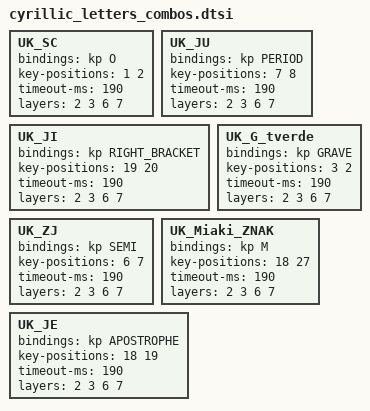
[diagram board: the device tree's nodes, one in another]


//---------------------------------------------    For OS in QWERTY    ---------------------------------------------
UK_SC {
    bindings = <&kp O>;
    key-positions = <1 2>;
    timeout-ms = <190>;
    layers = <2 3 6 7>;
};

UK_JU {
    bindings = <&kp PERIOD>;
    key-positions = <7 8>;
    timeout-ms = <190>;
    layers = <2 3 6 7>;
};

UK_JI {
    bindings = <&kp RIGHT_BRACKET>;
    key-positions = <19 20>;
    timeout-ms = <190>;
    layers = <2 3 6 7>;
};

UK_G_tverde {
    bindings = <&kp GRAVE>;
    key-positions = <3 2>;
    timeout-ms = <190>;
    layers = <2 3 6 7>;
};

UK_ZJ {
    bindings = <&kp SEMI>;
    key-positions = <6 7>;
    timeout-ms = <190>;
    layers = <2 3 6 7>;
};

UK_Miaki_ZNAK {
    bindings = <&kp M>;
    key-positions = <18 27>;
    timeout-ms = <190>;
    layers = <2 3 6 7>;
};

UK_JE {
    bindings = <&kp APOSTROPHE>;
    key-positions = <18 19>;
    timeout-ms = <190>;
    layers = <2 3 6 7>;
};

